# STM32N657 register map
File version: 1.0
CPU: CM55 r0p1, little endian, no MPU, FPU, vendor SysTick, 8 interrupt priority bits
Registers are 32-bit, read-write, reset 0x0 unless marked. A register's access mark holds for its fields unless they carry their own. Offsets are from the block's base; [hi:lo] are bit positions; {n}, {i} and the like mark numbered series.

## BSEC — Boot and security control
Base 0x46009000
Same registers: BSEC_S 0x56009000
{0x0+4i} FVR{i} (i=0..375) — BSEC fuse word {i} value register
  [31:0] FV — fuse value
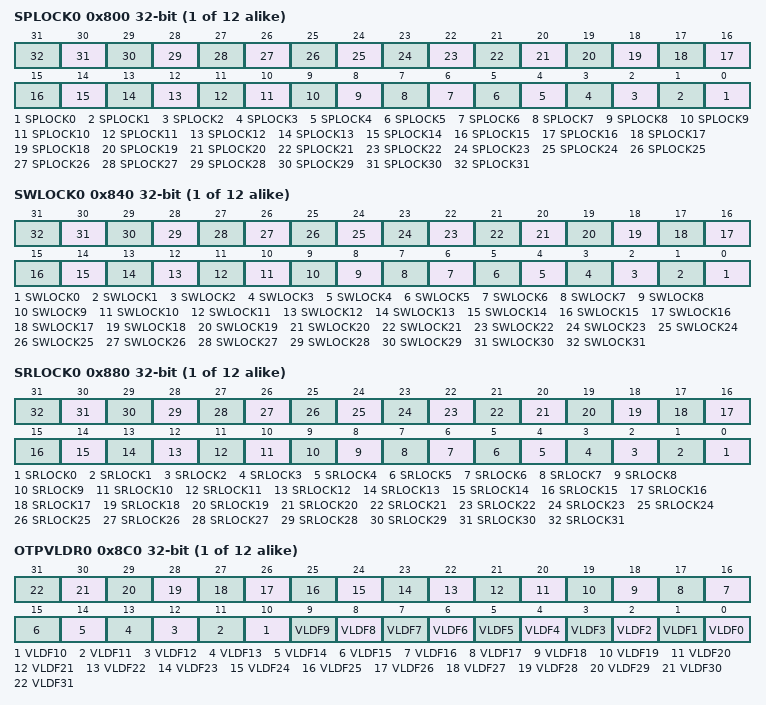
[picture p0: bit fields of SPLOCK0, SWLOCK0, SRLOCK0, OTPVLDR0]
{0x800+4i} SPLOCK{i} (i=0..11) — BSEC sticky programming lock register {i}
  [n] SPLOCK{n} (n=0..31) — Sticky programming lock for word {n}
{0x840+4i} SWLOCK{i} (i=0..11) — BSEC sticky write lock register {i}
  [n] SWLOCK{n} (n=0..31) — sticky write lock for shadow register {n}
{0x880+4i} SRLOCK{i} (i=0..11) — BSEC sticky reload lock register {i}
  [n] SRLOCK{n} (n=0..31) — sticky reload lock for fuse word {n}
{0x8C0+4i} OTPVLDR{i} (i=0..11) ro — BSEC OTP valid register {i}
  [n] VLDF{n} (n=0..31) — Valid flag for shadow register {n}
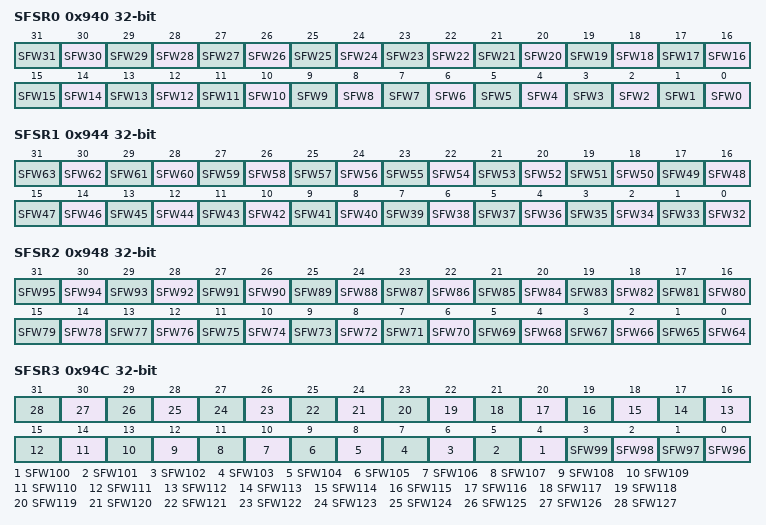
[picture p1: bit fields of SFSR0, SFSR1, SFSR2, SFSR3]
0x940 SFSR0 ro — BSEC shadowed fuses status register 0
  [n] SFW{n} (n=0..31) — Shadowed fuse word {n}
0x944 SFSR1 ro — BSEC shadowed fuses status register 1
  [n-32] SFW{n} (n=32..63) — Shadowed fuse word {n}
0x948 SFSR2 ro — BSEC shadowed fuses status register 2
  [n-64] SFW{n} (n=64..95) — Shadowed fuse word {n}
0x94C SFSR3 ro — BSEC shadowed fuses status register 3
  [n-96] SFW{n} (n=96..127) — Shadowed fuse word {n}
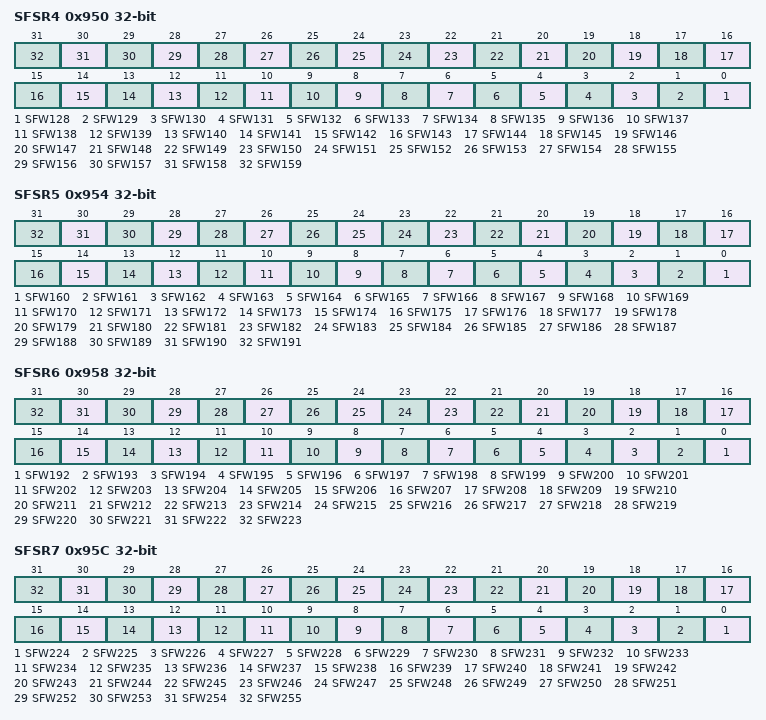
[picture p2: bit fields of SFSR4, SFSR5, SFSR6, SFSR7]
0x950 SFSR4 ro — BSEC shadowed fuses status register 4
  [n-128] SFW{n} (n=128..159) — Shadowed fuse word {n}
0x954 SFSR5 ro — BSEC shadowed fuses status register 5
  [n-160] SFW{n} (n=160..191) — Shadowed fuse word {n}
0x958 SFSR6 ro — BSEC shadowed fuses status register 6
  [n-192] SFW{n} (n=192..223) — Shadowed fuse word {n}
0x95C SFSR7 ro — BSEC shadowed fuses status register 7
  [n-224] SFW{n} (n=224..255) — Shadowed fuse word {n}
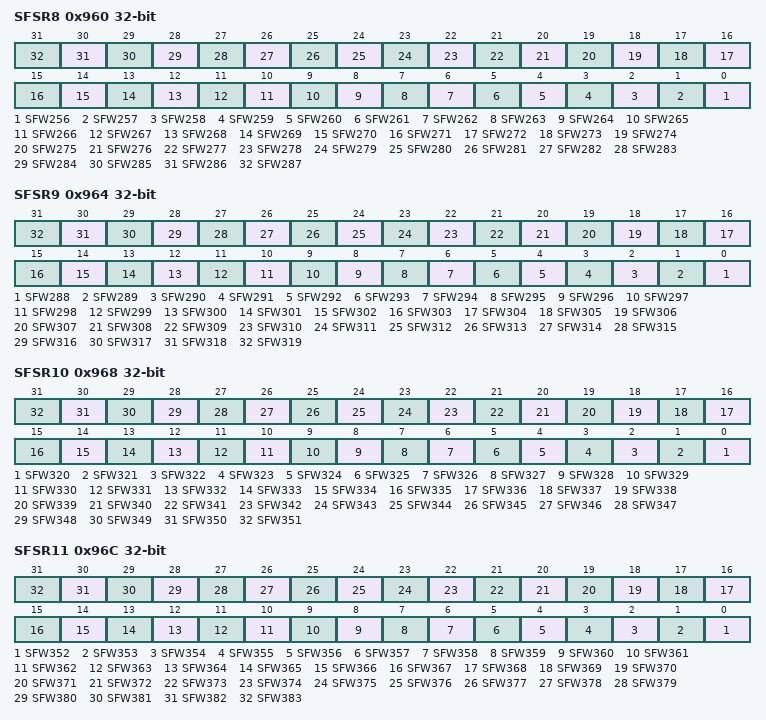
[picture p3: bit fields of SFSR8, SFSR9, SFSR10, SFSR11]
0x960 SFSR8 ro — BSEC shadowed fuses status register 8
  [n-256] SFW{n} (n=256..287) — Shadowed fuse word {n}
0x964 SFSR9 ro — BSEC shadowed fuses status register 9
  [n-288] SFW{n} (n=288..319) — Shadowed fuse word {n}
0x968 SFSR10 ro — BSEC shadowed fuses status register 10
  [n-320] SFW{n} (n=320..351) — Shadowed fuse word {n}
0x96C SFSR11 ro — BSEC shadowed fuses status register 11
  [n-352] SFW{n} (n=352..383) — Shadowed fuse word {n}
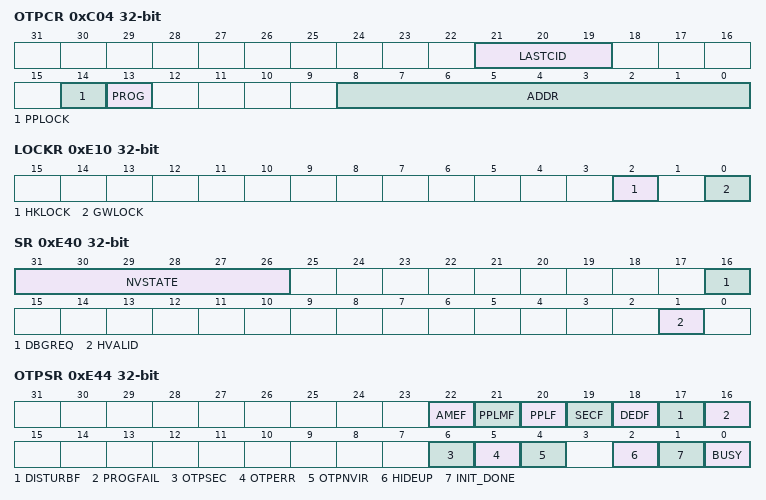
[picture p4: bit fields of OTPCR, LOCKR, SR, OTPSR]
0xC04 OTPCR access per field — BSEC OTP control register
  [21:19] LASTCID ro
  [14] PPLOCK rw — Permanent programming lock
  [13] PROG rw — Fuse word programming
  [8:0] ADDR rw — Fuse word address
0xC08 WDR wo — BSEC write data register
  [31:0] WRDATA — OTP write data
{0xE00+4i} SCRATCHR{i} (i=0..3) — BSEC scratch register {i}
  [31:0] SDATA — Scratch data
0xE10 LOCKR — BSEC lock register
  [2] HKLOCK — Hardware key lock
  [0] GWLOCK — Global write lock
0xE14 JTAGINR ro — BSEC JTAG input register
  [31:0] JDATAIN — JTAG input data
0xE18 JTAGOUTR wo — BSEC JTAG output register
  [31:0] JDATAOUT — JTAG output data
0xE24 UNMAPR — BSEC unmap register
  [31:0] UNMAP — Unmap key
0xE40 SR ro — BSEC status register
  [31:26] NVSTATE — Non-volatile state
  [16] DBGREQ — debug request
  [1] HVALID — Hardware key valid
0xE44 OTPSR ro — BSEC OTP status register
  [22] AMEF — Addresses mismatch error flag
  [21] PPLMF — Permanent programming lock mismatch flag
  [20] PPLF — Permanent programming lock flag
  [19] SECF — Single error correction flag
  [18] DEDF — Double error detection flag
  [17] DISTURBF — Disturb flag
  [16] PROGFAIL — Programming failed
  [6] OTPSEC — OTP with single error correction
  [5] OTPERR — OTP with error
  [4] OTPNVIR — OTP not virgin
  [2] HIDEUP — Hide upper fuse words
  [1] INIT_DONE — Initialization done
  [0] BUSY — Busy flag
{0xE80+4i} EPOCHR{i} (i=0..1) — BSEC epoch register
  [31:0] EPOCH
0xE88 EPOCH_SELR — BSEC epoch select register
  [0] EPSEL — Epoch selection. This value is wired out to the SAES peripheral.
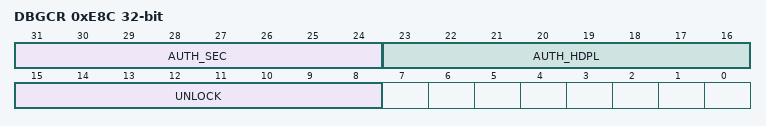
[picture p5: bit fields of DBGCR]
0xE8C DBGCR — BSEC Debug
  [31:24] AUTH_SEC — any other value: secure debug not authorized (provided BSEC state is not OPEN)
  [23:16] AUTH_HDPL — level at which debug may be opened.
  [15:8] UNLOCK — any other value: debug not authorized (provided BSEC state is not OPEN)
0xE90 AP_UNLOCK — BSEC AP Unlock
  [7:0] UNLOCK — any other value: do not unlock
0xE94 HDPLSR ro reset 0xB4 — BSEC HDPL
  [7:0] HDPL — current HDPL
0xE98 HDPLCR wo — BSEC HDPL control
  [31:0] INCR_HDPL — Increment HDPL
0xE9C NEXTLR — BSEC Next HDPL
  [1:0] INCR — Increment
{0xF40+4i} WOSCR{i} (i=0..7) rw-once — BSEC write once scratch register {i}
  [31:0] WOSDATA — Write once scratch data
0xFE8 HRCR ro — BSEC hot reset count register
  [31:0] HRC — hot reset counter
0xFEC WRCR ro — BSEC warm reset count register
  [31:0] WRC — Warm reset counter
